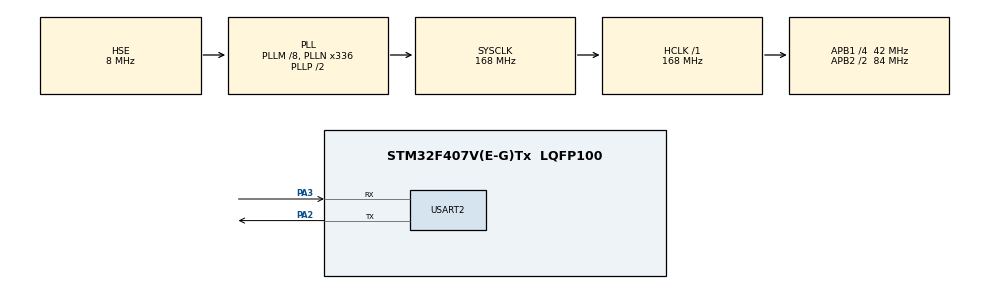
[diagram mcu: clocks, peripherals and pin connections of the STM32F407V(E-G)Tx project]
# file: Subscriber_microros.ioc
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Dma.Request0=USART2_RX
Dma.Request1=USART2_TX
Dma.USART2_RX.0.Direction=DMA_PERIPH_TO_MEMORY
Dma.USART2_RX.0.FIFOMode=DMA_FIFOMODE_DISABLE
Dma.USART2_RX.0.Instance=DMA1_Stream5
Dma.USART2_RX.0.MemDataAlignment=DMA_MDATAALIGN_BYTE
Dma.USART2_RX.0.MemInc=DMA_MINC_ENABLE
Dma.USART2_RX.0.Mode=DMA_NORMAL
Dma.USART2_RX.0.PeriphDataAlignment=DMA_PDATAALIGN_BYTE
Dma.USART2_RX.0.PeriphInc=DMA_PINC_DISABLE
Dma.USART2_RX.0.Priority=DMA_PRIORITY_VERY_HIGH
Dma.USART2_TX.1.Direction=DMA_MEMORY_TO_PERIPH
Dma.USART2_TX.1.FIFOMode=DMA_FIFOMODE_DISABLE
Dma.USART2_TX.1.Instance=DMA1_Stream6
Dma.USART2_TX.1.MemDataAlignment=DMA_MDATAALIGN_BYTE
Dma.USART2_TX.1.MemInc=DMA_MINC_ENABLE
Dma.USART2_TX.1.Mode=DMA_NORMAL
Dma.USART2_TX.1.PeriphDataAlignment=DMA_PDATAALIGN_BYTE
Dma.USART2_TX.1.PeriphInc=DMA_PINC_DISABLE
Dma.USART2_TX.1.Priority=DMA_PRIORITY_VERY_HIGH
FREERTOS.Tasks01=defaultTask,24,3000,StartDefaultTask,Default,NULL,Dynamic,NULL,NULL
Mcu.Family=STM32F4
Mcu.Name=STM32F407V(E-G)Tx
Mcu.Package=LQFP100
NVIC.DMA1_Stream5_IRQn=true\:5\:0\:false\:false\:true\:true\:false\:true\:true
NVIC.DMA1_Stream6_IRQn=true\:5\:0\:false\:false\:true\:true\:false\:true\:true
NVIC.PriorityGroup=NVIC_PRIORITYGROUP_4
NVIC.RCC_IRQn=true\:5\:0\:false\:false\:true\:true\:true\:false\:true
NVIC.USART2_IRQn=true\:5\:0\:false\:false\:true\:true\:true\:true\:true
PA13.Mode=Serial_Wire
PA13.Signal=SYS_JTMS-SWDIO
PA14.Mode=Serial_Wire
PA14.Signal=SYS_JTCK-SWCLK
PA2.Mode=Asynchronous
PA2.Signal=USART2_TX
PA3.Mode=Asynchronous
PA3.Signal=USART2_RX
PC14-OSC32_IN.Mode=LSE-External-Oscillator
PC14-OSC32_IN.Signal=RCC_OSC32_IN
PC15-OSC32_OUT.Mode=LSE-External-Oscillator
PC15-OSC32_OUT.Signal=RCC_OSC32_OUT
PH0-OSC_IN.Mode=HSE-External-Oscillator
PH0-OSC_IN.Signal=RCC_OSC_IN
PH1-OSC_OUT.Mode=HSE-External-Oscillator
PH1-OSC_OUT.Signal=RCC_OSC_OUT
ProjectManager.HeapSize=0x200
ProjectManager.StackSize=0x400
ProjectManager.TargetToolchain=STM32CubeIDE
RCC.48MHZClocksFreq_Value=48000000
RCC.AHBFreq_Value=168000000
RCC.APB1CLKDivider=RCC_HCLK_DIV4
RCC.APB1Freq_Value=42000000
RCC.APB1TimFreq_Value=84000000
RCC.APB2CLKDivider=RCC_HCLK_DIV2
RCC.APB2Freq_Value=84000000
RCC.APB2TimFreq_Value=168000000
RCC.CortexFreq_Value=168000000
RCC.HCLKFreq_Value=168000000
RCC.HSE_VALUE=8000000
RCC.HSI_VALUE=16000000
RCC.PLLM=8
RCC.PLLN=336
RCC.PLLQ=7
RCC.PLLSourceVirtual=RCC_PLLSOURCE_HSE
RCC.SYSCLKFreq_VALUE=168000000
RCC.SYSCLKSource=RCC_SYSCLKSOURCE_PLLCLK
RCC.VCOOutputFreq_Value=336000000
USART2.VirtualMode=VM_ASYNC
VP_FREERTOS_VS_CMSIS_V2.Mode=CMSIS_V2
board=STM32F407G-DISC1

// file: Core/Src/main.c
/* USER CODE BEGIN Header */
/**
  ******************************************************************************
  * @file           : main.c
  * @brief          : Main program body
  ******************************************************************************
  * @attention
  *
  * Copyright (c) 2023 STMicroelectronics.
  * All rights reserved.
  *
  * This software is licensed under terms that can be found in the LICENSE file
  * in the root directory of this software component.
  * If no LICENSE file comes with this software, it is provided AS-IS.
  *
  ******************************************************************************
  */
/* USER CODE END Header */
#include "main.h"
#include "cmsis_os.h"

/* USER CODE BEGIN Includes */
#include <rcl/rcl.h>
#include <rcl/error_handling.h>
#include <rclc/rclc.h>
#include <rclc/executor.h>
#include <uxr/client/transport.h>
#include <rmw_microxrcedds_c/config.h>
#include <rmw_microros/rmw_microros.h>

#include <std_msgs/msg/int32.h>
/* USER CODE END Includes */

/* USER CODE BEGIN PTD */
rcl_publisher_t publisher;
	  std_msgs__msg__Int32 msg;
	  rclc_support_t support;
	  rcl_allocator_t allocator;
	  rcl_node_t node;
	  rcl_subscription_t subscriber;
	  rclc_executor_t executor;
	  rcl_timer_t timer;
/* USER CODE END PTD */

/* USER CODE BEGIN PD */

/* USER CODE BEGIN PM */
void timer_callback(rcl_timer_t * timer, int64_t last_call_time)
{
	(void) last_call_time;
	if (timer != NULL) {
		rcl_publish(&publisher, &msg, NULL);
		printf("Sent: %d\n", msg.data);
		msg.data++;
	}
}

void subscription_callback(const void * msgin)
{
	const std_msgs__msg__Int32 * msg = (const std_msgs__msg__Int32 *)msgin;
	printf("Received: %d\n", msg->data);
}

/* USER CODE END PM */

UART_HandleTypeDef huart2;
DMA_HandleTypeDef hdma_usart2_rx;
DMA_HandleTypeDef hdma_usart2_tx;

/* Definitions for defaultTask */
osThreadId_t defaultTaskHandle;
const osThreadAttr_t defaultTask_attributes = {
  .name = "defaultTask",
  .stack_size = 3000 * 4,
  .priority = (osPriority_t) osPriorityNormal,
};

void SystemClock_Config(void);
static void MX_GPIO_Init(void);
static void MX_DMA_Init(void);
static void MX_USART2_UART_Init(void);
void StartDefaultTask(void *argument);

int main(void)
{

  /* MCU Configuration--------------------------------------------------------*/

  /* Reset of all peripherals, Initializes the Flash interface and the Systick. */
  HAL_Init();

  /* Configure the system clock */
  SystemClock_Config();

  /* Initialize all configured peripherals */
  MX_GPIO_Init();
  MX_DMA_Init();
  MX_USART2_UART_Init();

  /* Init scheduler */
  osKernelInitialize();

  /* Create the thread(s) */
  /* creation of defaultTask */
  defaultTaskHandle = osThreadNew(StartDefaultTask, NULL, &defaultTask_attributes);

  /* Start scheduler */
  osKernelStart();

  /* We should never get here as control is now taken by the scheduler */
  /* Infinite loop */
  while (1)
  {

  }
}

void SystemClock_Config(void)
{
  RCC_OscInitTypeDef RCC_OscInitStruct = {0};
  RCC_ClkInitTypeDef RCC_ClkInitStruct = {0};

  /** Configure the main internal regulator output voltage
  */
  __HAL_RCC_PWR_CLK_ENABLE();
  __HAL_PWR_VOLTAGESCALING_CONFIG(PWR_REGULATOR_VOLTAGE_SCALE1);

  /** Initializes the RCC Oscillators according to the specified parameters
  * in the RCC_OscInitTypeDef structure.
  */
  RCC_OscInitStruct.OscillatorType = RCC_OSCILLATORTYPE_HSE;
  RCC_OscInitStruct.HSEState = RCC_HSE_ON;
  RCC_OscInitStruct.PLL.PLLState = RCC_PLL_ON;
  RCC_OscInitStruct.PLL.PLLSource = RCC_PLLSOURCE_HSE;
  RCC_OscInitStruct.PLL.PLLM = 8;
  RCC_OscInitStruct.PLL.PLLN = 336;
  RCC_OscInitStruct.PLL.PLLP = RCC_PLLP_DIV2;
  RCC_OscInitStruct.PLL.PLLQ = 7;
  if (HAL_RCC_OscConfig(&RCC_OscInitStruct) != HAL_OK)
  {
    Error_Handler();
  }

  /** Initializes the CPU, AHB and APB buses clocks
  */
  RCC_ClkInitStruct.ClockType = RCC_CLOCKTYPE_HCLK|RCC_CLOCKTYPE_SYSCLK
                              |RCC_CLOCKTYPE_PCLK1|RCC_CLOCKTYPE_PCLK2;
  RCC_ClkInitStruct.SYSCLKSource = RCC_SYSCLKSOURCE_PLLCLK;
  RCC_ClkInitStruct.AHBCLKDivider = RCC_SYSCLK_DIV1;
  RCC_ClkInitStruct.APB1CLKDivider = RCC_HCLK_DIV4;
  RCC_ClkInitStruct.APB2CLKDivider = RCC_HCLK_DIV2;

  if (HAL_RCC_ClockConfig(&RCC_ClkInitStruct, FLASH_LATENCY_5) != HAL_OK)
  {
    Error_Handler();
  }
}

static void MX_USART2_UART_Init(void)
{

  huart2.Instance = USART2;
  huart2.Init.BaudRate = 115200;
  huart2.Init.WordLength = UART_WORDLENGTH_8B;
  huart2.Init.StopBits = UART_STOPBITS_1;
  huart2.Init.Parity = UART_PARITY_NONE;
  huart2.Init.Mode = UART_MODE_TX_RX;
  huart2.Init.HwFlowCtl = UART_HWCONTROL_NONE;
  huart2.Init.OverSampling = UART_OVERSAMPLING_16;
  if (HAL_UART_Init(&huart2) != HAL_OK)
  {
    Error_Handler();
  }

}

static void MX_DMA_Init(void)
{

  /* DMA controller clock enable */
  __HAL_RCC_DMA1_CLK_ENABLE();

  /* DMA interrupt init */
  /* DMA1_Stream5_IRQn interrupt configuration */
  HAL_NVIC_SetPriority(DMA1_Stream5_IRQn, 5, 0);
  HAL_NVIC_EnableIRQ(DMA1_Stream5_IRQn);
  /* DMA1_Stream6_IRQn interrupt configuration */
  HAL_NVIC_SetPriority(DMA1_Stream6_IRQn, 5, 0);
  HAL_NVIC_EnableIRQ(DMA1_Stream6_IRQn);

}

static void MX_GPIO_Init(void)
{

  /* GPIO Ports Clock Enable */
  __HAL_RCC_GPIOC_CLK_ENABLE();
  __HAL_RCC_GPIOH_CLK_ENABLE();
  __HAL_RCC_GPIOA_CLK_ENABLE();

}

/* USER CODE BEGIN 4 */
bool cubemx_transport_open(struct uxrCustomTransport * transport);
bool cubemx_transport_close(struct uxrCustomTransport * transport);
size_t cubemx_transport_write(struct uxrCustomTransport* transport, const uint8_t * buf, size_t len, uint8_t * err);
size_t cubemx_transport_read(struct uxrCustomTransport* transport, uint8_t* buf, size_t len, int timeout, uint8_t* err);

void * microros_allocate(size_t size, void * state);
void microros_deallocate(void * pointer, void * state);
void * microros_reallocate(void * pointer, size_t size, void * state);
void * microros_zero_allocate(size_t number_of_elements, size_t size_of_element, void * state);
/* USER CODE END 4 */

void StartDefaultTask(void *argument)
{
  /* USER CODE BEGIN 5 */

	  // micro-ROS configuration

	  rmw_uros_set_custom_transport(
	    true,
	    (void *) &huart2,
	    cubemx_transport_open,
	    cubemx_transport_close,
	    cubemx_transport_write,
	    cubemx_transport_read);

	  rcl_allocator_t freeRTOS_allocator = rcutils_get_zero_initialized_allocator();
	  freeRTOS_allocator.allocate = microros_allocate;
	  freeRTOS_allocator.deallocate = microros_deallocate;
	  freeRTOS_allocator.reallocate = microros_reallocate;
	  freeRTOS_allocator.zero_allocate =  microros_zero_allocate;

	  if (!rcutils_set_default_allocator(&freeRTOS_allocator)) {
	      printf("Error on default allocators (line %d)\n", __LINE__);
	  }

	  // micro-ROS app

	  rcl_publisher_t publisher;
	  	  std_msgs__msg__Int32 msg;
	  	  rclc_support_t support;
	  	  rcl_allocator_t allocator;
	  	  rcl_node_t node;
	  	  rcl_subscription_t subscriber;
	  	  rclc_executor_t executor;
	  	 // rcl_timer_t timer;

	  allocator = rcl_get_default_allocator();

	  //create init_options
	  rclc_support_init(&support, 0, NULL, &allocator);

	  // create node
	  rclc_node_init_default(&node, "cubemx_node", "STM32Discovery", &support);

	  //create publisher
	  rclc_publisher_init_default(
	    &publisher,
	    &node,
	    ROSIDL_GET_MSG_TYPE_SUPPORT(std_msgs, msg, Int32),
	    "count_sayi");

	  // create_subscriber
	  /*rclc_subscription_init_default(
	    &subscriber,
		&node,
		ROSIDL_GET_MSG_TYPE_SUPPORT(std_msgs, msg, Int32),
		"count_sayi");
*/

	  	// create executor
		/*rclc_executor_add_subscription(
			&executor, &subscriber,
			&msg,
			&subscription_callback,
			ON_NEW_DATA);

	  	rclc_executor_spin(&executor);*/

	  msg.data = 5;

	  for(;;)
	  {
	    rcl_ret_t ret = rcl_publish(&publisher, &msg, NULL);
	    if (ret != RCL_RET_OK)
	    {
	      printf("Error publishing (line %d)\n", __LINE__);
	    }
	   /* rcl_ret_t rc = rclc_executor_add_subscription(
	      &executor, &subscriber, &msg,
	      &subscription_callback, ON_NEW_DATA);
	    if (rc != RCL_RET_OK)
	    {
	    	printf("Error publishing (line %d)\n", __LINE__);
	    }*/

	   // rclc_executor_spin(&executor);
	    msg.data++;

	    osDelay(10);

	  }
  /* USER CODE END 5 */
}

void Error_Handler(void)
{
  __disable_irq();
  while (1)
  {
  }
}
